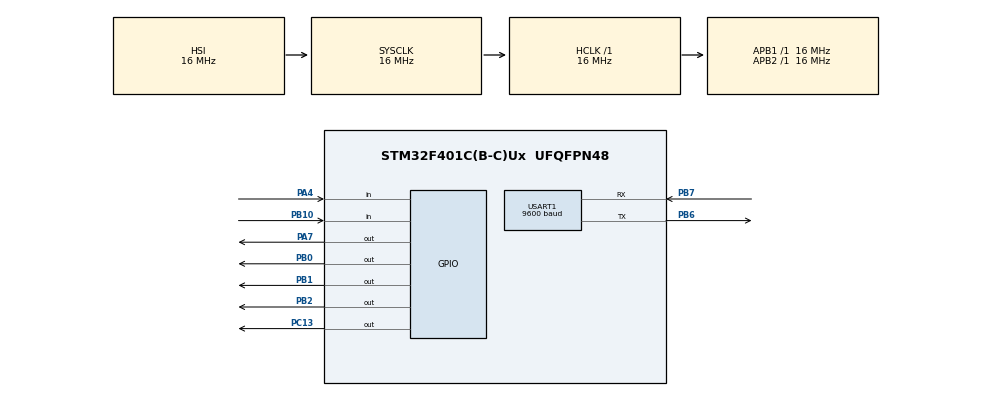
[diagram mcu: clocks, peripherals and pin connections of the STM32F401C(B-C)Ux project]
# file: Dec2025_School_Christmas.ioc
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IWDG.Prescaler=IWDG_PRESCALER_8
Mcu.Family=STM32F4
Mcu.Name=STM32F401C(B-C)Ux
Mcu.Package=UFQFPN48
NVIC.PriorityGroup=NVIC_PRIORITYGROUP_4
NVIC.TIM1_TRG_COM_TIM11_IRQn=true\:15\:0\:true\:true\:true\:1\:true\:true\:true
PA13.Mode=Serial_Wire
PA13.Signal=SYS_JTMS-SWDIO
PA14.Mode=Serial_Wire
PA14.Signal=SYS_JTCK-SWCLK
PA4.GPIO_PuPd=GPIO_PULLDOWN
PA4.Signal=GPIO_Input
PA7.GPIO_PuPd=GPIO_PULLDOWN
PA7.GPIO_Speed=GPIO_SPEED_FREQ_VERY_HIGH
PA7.Signal=GPIO_Output
PB0.GPIO_PuPd=GPIO_PULLDOWN
PB0.GPIO_Speed=GPIO_SPEED_FREQ_VERY_HIGH
PB0.Signal=GPIO_Output
PB1.GPIO_PuPd=GPIO_PULLDOWN
PB1.GPIO_Speed=GPIO_SPEED_FREQ_VERY_HIGH
PB1.Signal=GPIO_Output
PB10.GPIO_PuPd=GPIO_PULLUP
PB10.Signal=GPIO_Input
PB2.GPIO_PuPd=GPIO_PULLDOWN
PB2.GPIO_Speed=GPIO_SPEED_FREQ_VERY_HIGH
PB2.Signal=GPIO_Output
PB6.Mode=Asynchronous
PB6.Signal=USART1_TX
PB7.Mode=Asynchronous
PB7.Signal=USART1_RX
PC13-ANTI_TAMP.GPIO_PuPd=GPIO_PULLDOWN
PC13-ANTI_TAMP.Signal=GPIO_Output
ProjectManager.HeapSize=0x400
ProjectManager.StackSize=0x800
ProjectManager.TargetToolchain=MDK-ARM V5.32
RCC.AHBFreq_Value=16000000
RCC.APB1Freq_Value=16000000
RCC.APB2Freq_Value=16000000
RCC.CortexFreq_Value=16000000
RCC.HSE_VALUE=25000000
RCC.HSI_VALUE=16000000
RCC.LSE_VALUE=32768
RCC.SYSCLKFreq_VALUE=16000000
RCC.VCOOutputFreq_Value=192000000
TIM11.AutoReloadPreload=TIM_AUTORELOAD_PRELOAD_ENABLE
TIM11.Period=99
TIM11.Prescaler=159
USART1.BaudRate=9600
USART1.VirtualMode=VM_ASYNC
VP_IWDG_VS_IWDG.Mode=IWDG_Activate
VP_TIM11_VS_ClockSourceINT.Mode=Enable_Timer
board=custom

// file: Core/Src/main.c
/* USER CODE BEGIN Header */
/**
  ******************************************************************************
  * @file           : main.c
  * @brief          : Main program body
  ******************************************************************************
  * @attention
  *
  * Copyright (c) 2025 STMicroelectronics.
  * All rights reserved.
  *
  * This software is licensed under terms that can be found in the LICENSE file
  * in the root directory of this software component.
  * If no LICENSE file comes with this software, it is provided AS-IS.
  *
  ******************************************************************************
  */
/* USER CODE END Header */
#include "main.h"

/* USER CODE BEGIN Includes */
#include "Proj_Header.h"
/* USER CODE END Includes */

TIM_HandleTypeDef htim11;

UART_HandleTypeDef huart1;

void SystemClock_Config(void);
static void MX_GPIO_Init(void);
static void MX_TIM11_Init(void);
static void MX_USART1_UART_Init(void);
static void MX_NVIC_Init(void);

int main(void)
{

  /* MCU Configuration--------------------------------------------------------*/

  /* Reset of all peripherals, Initializes the Flash interface and the Systick. */
  HAL_Init();

  /* Configure the system clock */
  SystemClock_Config();

  /* Initialize all configured peripherals */
  MX_GPIO_Init();
  MX_TIM11_Init();
  MX_USART1_UART_Init();

  /* Initialize interrupts */
  MX_NVIC_Init();
  /* USER CODE BEGIN 2 */
	init_function();
  /* USER CODE END 2 */

  /* Infinite loop */
  while (1)
  {

    /* USER CODE BEGIN 3 */
		while_function();
  }
  /* USER CODE END 3 */
}

void SystemClock_Config(void)
{
  RCC_OscInitTypeDef RCC_OscInitStruct = {0};
  RCC_ClkInitTypeDef RCC_ClkInitStruct = {0};

  /** Configure the main internal regulator output voltage
  */
  __HAL_RCC_PWR_CLK_ENABLE();
  __HAL_PWR_VOLTAGESCALING_CONFIG(PWR_REGULATOR_VOLTAGE_SCALE2);

  /** Initializes the RCC Oscillators according to the specified parameters
  * in the RCC_OscInitTypeDef structure.
  */
  RCC_OscInitStruct.OscillatorType = RCC_OSCILLATORTYPE_HSI;
  RCC_OscInitStruct.HSIState = RCC_HSI_ON;
  RCC_OscInitStruct.HSICalibrationValue = RCC_HSICALIBRATION_DEFAULT;
  RCC_OscInitStruct.PLL.PLLState = RCC_PLL_NONE;
  if (HAL_RCC_OscConfig(&RCC_OscInitStruct) != HAL_OK)
  {
    Error_Handler();
  }

  /** Initializes the CPU, AHB and APB buses clocks
  */
  RCC_ClkInitStruct.ClockType = RCC_CLOCKTYPE_HCLK|RCC_CLOCKTYPE_SYSCLK
                              |RCC_CLOCKTYPE_PCLK1|RCC_CLOCKTYPE_PCLK2;
  RCC_ClkInitStruct.SYSCLKSource = RCC_SYSCLKSOURCE_HSI;
  RCC_ClkInitStruct.AHBCLKDivider = RCC_SYSCLK_DIV1;
  RCC_ClkInitStruct.APB1CLKDivider = RCC_HCLK_DIV1;
  RCC_ClkInitStruct.APB2CLKDivider = RCC_HCLK_DIV1;

  if (HAL_RCC_ClockConfig(&RCC_ClkInitStruct, FLASH_LATENCY_0) != HAL_OK)
  {
    Error_Handler();
  }
}

/**
  * @brief NVIC Configuration.
  * @retval None
  */
static void MX_NVIC_Init(void)
{
  /* TIM1_TRG_COM_TIM11_IRQn interrupt configuration */
  HAL_NVIC_SetPriority(TIM1_TRG_COM_TIM11_IRQn, 15, 0);
  HAL_NVIC_EnableIRQ(TIM1_TRG_COM_TIM11_IRQn);
}

static void MX_TIM11_Init(void)
{

  htim11.Instance = TIM11;
  htim11.Init.Prescaler = 159;
  htim11.Init.CounterMode = TIM_COUNTERMODE_UP;
  htim11.Init.Period = 99;
  htim11.Init.ClockDivision = TIM_CLOCKDIVISION_DIV1;
  htim11.Init.AutoReloadPreload = TIM_AUTORELOAD_PRELOAD_ENABLE;
  if (HAL_TIM_Base_Init(&htim11) != HAL_OK)
  {
    Error_Handler();
  }

}

static void MX_USART1_UART_Init(void)
{

  huart1.Instance = USART1;
  huart1.Init.BaudRate = 9600;
  huart1.Init.WordLength = UART_WORDLENGTH_8B;
  huart1.Init.StopBits = UART_STOPBITS_1;
  huart1.Init.Parity = UART_PARITY_NONE;
  huart1.Init.Mode = UART_MODE_TX_RX;
  huart1.Init.HwFlowCtl = UART_HWCONTROL_NONE;
  huart1.Init.OverSampling = UART_OVERSAMPLING_16;
  if (HAL_UART_Init(&huart1) != HAL_OK)
  {
    Error_Handler();
  }

}

static void MX_GPIO_Init(void)
{
  GPIO_InitTypeDef GPIO_InitStruct = {0};

  /* GPIO Ports Clock Enable */
  __HAL_RCC_GPIOC_CLK_ENABLE();
  __HAL_RCC_GPIOA_CLK_ENABLE();
  __HAL_RCC_GPIOB_CLK_ENABLE();

  /*Configure GPIO pin Output Level */
  HAL_GPIO_WritePin(GPIOC, GPIO_PIN_13, GPIO_PIN_RESET);

  /*Configure GPIO pin Output Level */
  HAL_GPIO_WritePin(GPIOA, GPIO_PIN_7, GPIO_PIN_RESET);

  /*Configure GPIO pin Output Level */
  HAL_GPIO_WritePin(GPIOB, GPIO_PIN_0|GPIO_PIN_1|GPIO_PIN_2, GPIO_PIN_RESET);

  /*Configure GPIO pin : PC13 */
  GPIO_InitStruct.Pin = GPIO_PIN_13;
  GPIO_InitStruct.Mode = GPIO_MODE_OUTPUT_PP;
  GPIO_InitStruct.Pull = GPIO_PULLDOWN;
  GPIO_InitStruct.Speed = GPIO_SPEED_FREQ_LOW;
  HAL_GPIO_Init(GPIOC, &GPIO_InitStruct);

  /*Configure GPIO pin : PA7 */
  GPIO_InitStruct.Pin = GPIO_PIN_7;
  GPIO_InitStruct.Mode = GPIO_MODE_OUTPUT_PP;
  GPIO_InitStruct.Pull = GPIO_PULLDOWN;
  GPIO_InitStruct.Speed = GPIO_SPEED_FREQ_VERY_HIGH;
  HAL_GPIO_Init(GPIOA, &GPIO_InitStruct);

  /*Configure GPIO pins : PB0 PB1 PB2 */
  GPIO_InitStruct.Pin = GPIO_PIN_0|GPIO_PIN_1|GPIO_PIN_2;
  GPIO_InitStruct.Mode = GPIO_MODE_OUTPUT_PP;
  GPIO_InitStruct.Pull = GPIO_PULLDOWN;
  GPIO_InitStruct.Speed = GPIO_SPEED_FREQ_VERY_HIGH;
  HAL_GPIO_Init(GPIOB, &GPIO_InitStruct);

  /*Configure GPIO pin : PB10 */
  GPIO_InitStruct.Pin = GPIO_PIN_10;
  GPIO_InitStruct.Mode = GPIO_MODE_INPUT;
  GPIO_InitStruct.Pull = GPIO_PULLUP;
  HAL_GPIO_Init(GPIOB, &GPIO_InitStruct);

}

void Error_Handler(void)
{
  __disable_irq();
  while (1)
  {
  }
}
